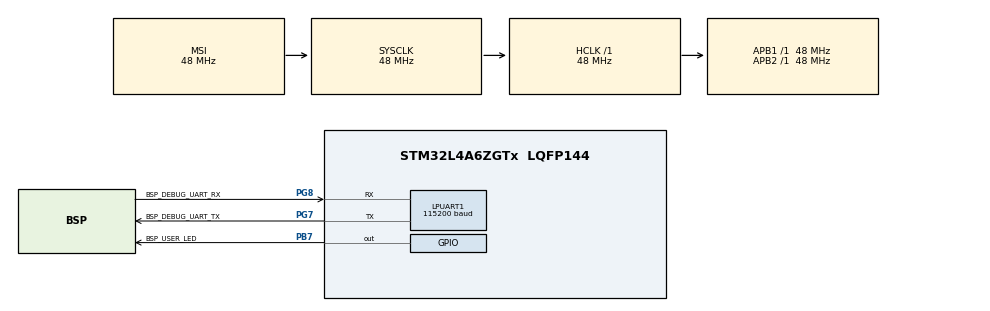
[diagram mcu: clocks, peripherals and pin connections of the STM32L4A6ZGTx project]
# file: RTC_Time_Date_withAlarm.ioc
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LPUART1.BaudRate=115200
LPUART1.WordLength=UART_WORDLENGTH_8B
Mcu.Family=STM32L4
Mcu.Name=STM32L4A6ZGTx
Mcu.Package=LQFP144
NVIC.PriorityGroup=NVIC_PRIORITYGROUP_4
NVIC.RTC_Alarm_IRQn=true\:0\:0\:false\:false\:true\:true\:true\:true
PB7.GPIO_Label=BSP_USER_LED
PB7.Signal=GPIO_Output
PC14-OSC32_IN\ (PC14).Mode=LSE-External-Oscillator
PC14-OSC32_IN\ (PC14).Signal=RCC_OSC32_IN
PC15-OSC32_OUT\ (PC15).Mode=LSE-External-Oscillator
PC15-OSC32_OUT\ (PC15).Signal=RCC_OSC32_OUT
PG7.GPIO_Label=BSP_DEBUG_UART_TX
PG7.Mode=Asynchronous
PG7.Signal=LPUART1_TX
PG8.GPIO_Label=BSP_DEBUG_UART_RX
PG8.Mode=Asynchronous
PG8.Signal=LPUART1_RX
PH0-OSC_IN\ (PH0).Mode=HSE-External-Oscillator
PH0-OSC_IN\ (PH0).Signal=RCC_OSC_IN
PH1-OSC_OUT\ (PH1).Mode=HSE-External-Oscillator
PH1-OSC_OUT\ (PH1).Signal=RCC_OSC_OUT
ProjectManager.HeapSize=0x200
ProjectManager.StackSize=0x400
ProjectManager.TargetToolchain=STM32CubeIDE
RCC.ADCFreq_Value=32000000
RCC.AHBFreq_Value=48000000
RCC.APB1Freq_Value=48000000
RCC.APB1TimFreq_Value=48000000
RCC.APB2Freq_Value=48000000
RCC.APB2TimFreq_Value=48000000
RCC.CortexFreq_Value=48000000
RCC.HCLKFreq_Value=48000000
RCC.HSE_VALUE=8000000
RCC.HSI48_VALUE=48000000
RCC.HSI_VALUE=16000000
RCC.MSIClockRange=RCC_MSIRANGE_11
RCC.MSI_VALUE=48000000
RCC.PLLN=20
RCC.PLLSourceVirtual=RCC_PLLSOURCE_HSE
RCC.RTCClockSelection=RCC_RTCCLKSOURCE_LSE
RCC.SYSCLKFreq_VALUE=48000000
RCC.USBFreq_Value=32000000
RCC.VCOOutputFreq_Value=160000000
RTC.Alarm-Alarm\ A=RTC_ALARM_A
RTC.AlarmDateWeekDay-Alarm\ A=14
RTC.AlarmMaskDateWeekDay-Alarm\ A=RTC_ALARMMASK_DATEWEEKDAY
RTC.AlarmMaskHours-Alarm\ A=RTC_ALARMMASK_HOURS
RTC.AlarmMaskMinutes-Alarm\ A=RTC_ALARMMASK_MINUTES
RTC.Date=14
RTC.Format=RTC_FORMAT_BCD
RTC.HourFormat=RTC_HOURFORMAT_24
RTC.Hours=10
RTC.Hours_A-Alarm\ A=0
RTC.Minutes=20
RTC.Minutes_A-Alarm\ A=0
RTC.Month=RTC_MONTH_MAY
RTC.Seconds=30
RTC.SubSeconds_A-Alarm\ A=0
RTC.WeekDay=RTC_WEEKDAY_TUESDAY
RTC.Year=24
VP_RTC_VS_RTC_Activate.Mode=RTC_Enabled
VP_RTC_VS_RTC_Alarm_A_Intern.Mode=Alarm A
VP_RTC_VS_RTC_Calendar.Mode=RTC_Calendar
board=NUCLEO-L4A6ZG

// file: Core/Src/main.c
/* USER CODE BEGIN Header */
/**
  ******************************************************************************
  * @file           : main.c
  * @brief          : Main program body
  ******************************************************************************
  * @attention
  *
  * Copyright (c) 2024 STMicroelectronics.
  * All rights reserved.
  *
  * This software is licensed under terms that can be found in the LICENSE file
  * in the root directory of this software component.
  * If no LICENSE file comes with this software, it is provided AS-IS.
  *
  ******************************************************************************
  */
/* USER CODE END Header */
#include "main.h"

/* USER CODE BEGIN Includes */
#include "string.h"
#include <stdio.h>
/* USER CODE END Includes */

UART_HandleTypeDef hlpuart1;

RTC_HandleTypeDef hrtc;

/* USER CODE BEGIN PV */

char timeString[20];
uint8_t count = 0;
RTC_TimeTypeDef sTime = {0};
RTC_DateTypeDef sDate = {0};
RTC_AlarmTypeDef sAlarm = {0};

/* USER CODE END PV */

void SystemClock_Config(void);
static void MX_GPIO_Init(void);
static void MX_LPUART1_UART_Init(void);
static void MX_RTC_Init(void);
/* USER CODE BEGIN PFP */
void HAL_RTC_AlarmAEventCallback(RTC_HandleTypeDef *hrtc);
/* USER CODE END PFP */

int main(void)
{

  /* MCU Configuration--------------------------------------------------------*/

  /* Reset of all peripherals, Initializes the Flash interface and the Systick. */
  HAL_Init();

  /* Configure the system clock */
  SystemClock_Config();

  /* Initialize all configured peripherals */
  MX_GPIO_Init();
  MX_LPUART1_UART_Init();
  MX_RTC_Init();

  /* Infinite loop */
  while (1)
  {

    /* USER CODE BEGIN 3 */

	  	  /* Get the current time and date from rtc */
	if (HAL_RTC_GetTime(&hrtc, &sTime, RTC_FORMAT_BIN) == HAL_OK
				&& HAL_RTC_GetDate(&hrtc, &sDate, RTC_FORMAT_BIN) == HAL_OK)
	{
		/*print the date and time on terminal */
		printf("Time: %02d:%02d:%02d Date: %02d/%02d/%02d\r\n", sTime.Hours,
				sTime.Minutes, sTime.Seconds, sDate.Date, sDate.Month,
				2000 + sDate.Year);
	}

	/* If you want to print using UART
	 * uncomment the below line */
	//HAL_UART_Transmit(&hlpuart1, (uint8_t *)timeString, strlen(timeString), HAL_MAX_DELAY);

	HAL_Delay(1000);		//delay for 1 sec
  }
  /* USER CODE END 3 */
}

void SystemClock_Config(void)
{
  RCC_OscInitTypeDef RCC_OscInitStruct = {0};
  RCC_ClkInitTypeDef RCC_ClkInitStruct = {0};

  /** Configure the main internal regulator output voltage
  */
  if (HAL_PWREx_ControlVoltageScaling(PWR_REGULATOR_VOLTAGE_SCALE1) != HAL_OK)
  {
    Error_Handler();
  }

  /** Configure LSE Drive Capability
  */
  HAL_PWR_EnableBkUpAccess();
  __HAL_RCC_LSEDRIVE_CONFIG(RCC_LSEDRIVE_LOW);

  /** Initializes the RCC Oscillators according to the specified parameters
  * in the RCC_OscInitTypeDef structure.
  */
  RCC_OscInitStruct.OscillatorType = RCC_OSCILLATORTYPE_LSE|RCC_OSCILLATORTYPE_MSI;
  RCC_OscInitStruct.LSEState = RCC_LSE_ON;
  RCC_OscInitStruct.MSIState = RCC_MSI_ON;
  RCC_OscInitStruct.MSICalibrationValue = 0;
  RCC_OscInitStruct.MSIClockRange = RCC_MSIRANGE_11;
  RCC_OscInitStruct.PLL.PLLState = RCC_PLL_NONE;
  if (HAL_RCC_OscConfig(&RCC_OscInitStruct) != HAL_OK)
  {
    Error_Handler();
  }

  /** Initializes the CPU, AHB and APB buses clocks
  */
  RCC_ClkInitStruct.ClockType = RCC_CLOCKTYPE_HCLK|RCC_CLOCKTYPE_SYSCLK
                              |RCC_CLOCKTYPE_PCLK1|RCC_CLOCKTYPE_PCLK2;
  RCC_ClkInitStruct.SYSCLKSource = RCC_SYSCLKSOURCE_MSI;
  RCC_ClkInitStruct.AHBCLKDivider = RCC_SYSCLK_DIV1;
  RCC_ClkInitStruct.APB1CLKDivider = RCC_HCLK_DIV1;
  RCC_ClkInitStruct.APB2CLKDivider = RCC_HCLK_DIV1;

  if (HAL_RCC_ClockConfig(&RCC_ClkInitStruct, FLASH_LATENCY_2) != HAL_OK)
  {
    Error_Handler();
  }
}

static void MX_LPUART1_UART_Init(void)
{

  hlpuart1.Instance = LPUART1;
  hlpuart1.Init.BaudRate = 115200;
  hlpuart1.Init.WordLength = UART_WORDLENGTH_8B;
  hlpuart1.Init.StopBits = UART_STOPBITS_1;
  hlpuart1.Init.Parity = UART_PARITY_NONE;
  hlpuart1.Init.Mode = UART_MODE_TX_RX;
  hlpuart1.Init.HwFlowCtl = UART_HWCONTROL_NONE;
  hlpuart1.Init.OneBitSampling = UART_ONE_BIT_SAMPLE_DISABLE;
  hlpuart1.AdvancedInit.AdvFeatureInit = UART_ADVFEATURE_NO_INIT;
  if (HAL_UART_Init(&hlpuart1) != HAL_OK)
  {
    Error_Handler();
  }

}

static void MX_RTC_Init(void)
{

  RTC_TimeTypeDef sTime = {0};
  RTC_DateTypeDef sDate = {0};
  RTC_AlarmTypeDef sAlarm = {0};

  /** Initialize RTC Only
  */
  hrtc.Instance = RTC;
  hrtc.Init.HourFormat = RTC_HOURFORMAT_24;
  hrtc.Init.AsynchPrediv = 127;
  hrtc.Init.SynchPrediv = 255;
  hrtc.Init.OutPut = RTC_OUTPUT_DISABLE;
  hrtc.Init.OutPutRemap = RTC_OUTPUT_REMAP_NONE;
  hrtc.Init.OutPutPolarity = RTC_OUTPUT_POLARITY_HIGH;
  hrtc.Init.OutPutType = RTC_OUTPUT_TYPE_OPENDRAIN;
  if (HAL_RTC_Init(&hrtc) != HAL_OK)
  {
    Error_Handler();
  }

  /* USER CODE BEGIN Check_RTC_BKUP */

//	HAL_RTCEx_BKUPWrite(&hrtc, RTC_BKP_DR1, 0x32F2);

  /* USER CODE END Check_RTC_BKUP */

  /** Initialize RTC and set the Time and Date
  */
  sTime.Hours = 0x10;
  sTime.Minutes = 0x20;
  sTime.Seconds = 0x00;
  sTime.DayLightSaving = RTC_DAYLIGHTSAVING_NONE;
  sTime.StoreOperation = RTC_STOREOPERATION_RESET;
  if (HAL_RTC_SetTime(&hrtc, &sTime, RTC_FORMAT_BCD) != HAL_OK)
  {
    Error_Handler();
  }
  sDate.WeekDay = RTC_WEEKDAY_TUESDAY;
  sDate.Month = RTC_MONTH_MAY;
  sDate.Date = 0x14;
  sDate.Year = 0x24;

  if (HAL_RTC_SetDate(&hrtc, &sDate, RTC_FORMAT_BCD) != HAL_OK)
  {
    Error_Handler();
  }

  /** Enable the Alarm A
  */
  sAlarm.AlarmTime.Hours = 0x0;
  sAlarm.AlarmTime.Minutes = 0x0;
  sAlarm.AlarmTime.Seconds = 0x00;
  sAlarm.AlarmTime.SubSeconds = 0x10;
  sAlarm.AlarmTime.DayLightSaving = RTC_DAYLIGHTSAVING_NONE;
  sAlarm.AlarmTime.StoreOperation = RTC_STOREOPERATION_RESET;
  sAlarm.AlarmMask = RTC_ALARMMASK_DATEWEEKDAY|RTC_ALARMMASK_HOURS
                              |RTC_ALARMMASK_MINUTES;
  sAlarm.AlarmSubSecondMask = RTC_ALARMSUBSECONDMASK_ALL;
  sAlarm.AlarmDateWeekDaySel = RTC_ALARMDATEWEEKDAYSEL_DATE;
  sAlarm.AlarmDateWeekDay = 0x14;
  sAlarm.Alarm = RTC_ALARM_A;
  if (HAL_RTC_SetAlarm_IT(&hrtc, &sAlarm, RTC_FORMAT_BCD) != HAL_OK)
  {
    Error_Handler();
  }

}

static void MX_GPIO_Init(void)
{
  GPIO_InitTypeDef GPIO_InitStruct = {0};

  /* GPIO Ports Clock Enable */
  __HAL_RCC_GPIOC_CLK_ENABLE();
  __HAL_RCC_GPIOH_CLK_ENABLE();
  __HAL_RCC_GPIOG_CLK_ENABLE();
  HAL_PWREx_EnableVddIO2();
  __HAL_RCC_GPIOB_CLK_ENABLE();

  /*Configure GPIO pin Output Level */
  HAL_GPIO_WritePin(BSP_USER_LED_GPIO_Port, BSP_USER_LED_Pin, GPIO_PIN_RESET);

  /*Configure GPIO pin : BSP_USER_LED_Pin */
  GPIO_InitStruct.Pin = BSP_USER_LED_Pin;
  GPIO_InitStruct.Mode = GPIO_MODE_OUTPUT_PP;
  GPIO_InitStruct.Pull = GPIO_NOPULL;
  GPIO_InitStruct.Speed = GPIO_SPEED_FREQ_LOW;
  HAL_GPIO_Init(BSP_USER_LED_GPIO_Port, &GPIO_InitStruct);

}

/* USER CODE BEGIN 4 */

void HAL_RTC_AlarmAEventCallback(RTC_HandleTypeDef *hrtc)
{
	/* Handle the callback funtion */

	count++;		//increment the count

	/* we need alarm event after every 2 minutes */
	if (count == 2)
	{
		/* turn on led at alarm time */
		HAL_GPIO_WritePin(BSP_USER_LED_GPIO_Port, BSP_USER_LED_Pin, GPIO_PIN_SET);
		/* print the msg on terminal */
		printf("Alarm On\r\n");

		/* Reset the count */
		count = 0;

	}
	else	//turn off led after alarm event
	{
		HAL_GPIO_WritePin(BSP_USER_LED_GPIO_Port, BSP_USER_LED_Pin, GPIO_PIN_RESET);
	}
}

/* USER CODE END 4 */

void Error_Handler(void)
{
  __disable_irq();
  while (1)
  {
  }
}
